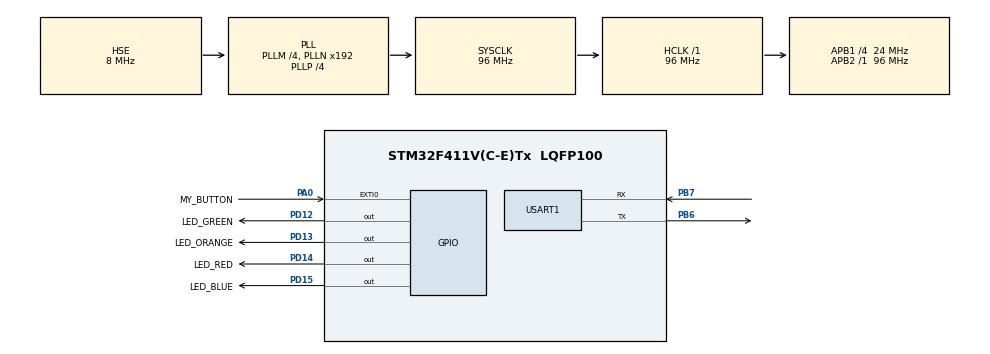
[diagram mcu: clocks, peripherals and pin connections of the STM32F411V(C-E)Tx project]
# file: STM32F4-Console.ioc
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Mcu.Family=STM32F4
Mcu.Name=STM32F411V(C-E)Tx
Mcu.Package=LQFP100
NVIC.EXTI0_IRQn=true\:0\:0\:false\:false\:true\:true\:true\:true
NVIC.PriorityGroup=NVIC_PRIORITYGROUP_0
NVIC.USART1_IRQn=true\:0\:0\:false\:false\:true\:true\:true\:true
PA0-WKUP.GPIO_Label=MY_BUTTON
PA0-WKUP.GPIO_ModeDefaultEXTI=GPIO_MODE_IT_RISING
PA0-WKUP.GPIO_PuPd=GPIO_PULLDOWN
PA0-WKUP.Signal=GPXTI0
PA13.GPIO_Label=SWDIO
PA13.Mode=Serial_Wire
PA13.Signal=SYS_JTMS-SWDIO
PA14.GPIO_Label=SWCLK
PA14.Mode=Serial_Wire
PA14.Signal=SYS_JTCK-SWCLK
PB6.Mode=Asynchronous
PB6.Signal=USART1_TX
PB7.Mode=Asynchronous
PB7.Signal=USART1_RX
PC14-OSC32_IN.GPIO_Label=PC14-OSC32_IN
PC14-OSC32_IN.Mode=LSE-External-Oscillator
PC14-OSC32_IN.Signal=RCC_OSC32_IN
PC15-OSC32_OUT.GPIO_Label=PC15-OSC32_OUT
PC15-OSC32_OUT.Mode=LSE-External-Oscillator
PC15-OSC32_OUT.Signal=RCC_OSC32_OUT
PD12.GPIO_Label=LED_GREEN
PD12.GPIO_PuPd=GPIO_NOPULL
PD12.GPIO_Speed=GPIO_SPEED_FREQ_LOW
PD12.Signal=GPIO_Output
PD13.GPIO_Label=LED_ORANGE
PD13.GPIO_PuPd=GPIO_NOPULL
PD13.GPIO_Speed=GPIO_SPEED_FREQ_LOW
PD13.Signal=GPIO_Output
PD14.GPIO_Label=LED_RED
PD14.GPIO_PuPd=GPIO_NOPULL
PD14.GPIO_Speed=GPIO_SPEED_FREQ_LOW
PD14.Signal=GPIO_Output
PD15.GPIO_Label=LED_BLUE
PD15.GPIO_PuPd=GPIO_NOPULL
PD15.GPIO_Speed=GPIO_SPEED_FREQ_LOW
PD15.Signal=GPIO_Output
PH0\ -\ OSC_IN.GPIO_Label=PH0-OSC_IN
PH0\ -\ OSC_IN.Mode=HSE-External-Oscillator
PH0\ -\ OSC_IN.Signal=RCC_OSC_IN
PH1\ -\ OSC_OUT.GPIO_Label=PH1-OSC_OUT
PH1\ -\ OSC_OUT.Mode=HSE-External-Oscillator
PH1\ -\ OSC_OUT.Signal=RCC_OSC_OUT
ProjectManager.HeapSize=0x200
ProjectManager.StackSize=0x400
ProjectManager.TargetToolchain=STM32CubeIDE
RCC.48MHZClocksFreq_Value=48000000
RCC.AHBFreq_Value=96000000
RCC.APB1CLKDivider=RCC_HCLK_DIV4
RCC.APB1Freq_Value=24000000
RCC.APB1TimFreq_Value=48000000
RCC.APB2Freq_Value=96000000
RCC.APB2TimFreq_Value=96000000
RCC.CortexFreq_Value=96000000
RCC.HCLKFreq_Value=96000000
RCC.HSE_VALUE=8000000
RCC.HSI_VALUE=16000000
RCC.PLLI2SM=5
RCC.PLLI2SN=200
RCC.PLLM=4
RCC.PLLP=RCC_PLLP_DIV4
RCC.PLLQ=8
RCC.PLLSourceVirtual=RCC_PLLSOURCE_HSE
RCC.SYSCLKFreq_VALUE=96000000
RCC.SYSCLKSource=RCC_SYSCLKSOURCE_PLLCLK
RCC.VCOOutputFreq_Value=384000000
USART1.VirtualMode=VM_ASYNC
board=STM32F411E-DISCO

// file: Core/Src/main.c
/* USER CODE BEGIN Header */
/**
  ******************************************************************************
  * @file           : main.c
  * @brief          : Main program body
  ******************************************************************************
  * @attention
  *
  * Copyright (c) 2023 STMicroelectronics.
  * All rights reserved.
  *
  * This software is licensed under terms that can be found in the LICENSE file
  * in the root directory of this software component.
  * If no LICENSE file comes with this software, it is provided AS-IS.
  *
  ******************************************************************************
  */
/* USER CODE END Header */
#include "main.h"

/* USER CODE BEGIN Includes */
#include <stdio.h>
#include <string.h>
#include "console.h"
/* USER CODE END Includes */

UART_HandleTypeDef huart1;

void SystemClock_Config(void);
static void MX_GPIO_Init(void);
static void MX_USART1_UART_Init(void);

/* USER CODE BEGIN 0 */
// ISR - Callback Functions
void HAL_GPIO_EXTI_Callback(uint16_t GPIO_Pin)
{
    if(GPIO_Pin == GPIO_PIN_0){
            HAL_GPIO_TogglePin(LED_BLUE_GPIO_Port, LED_BLUE_Pin);
        }
}

/* USER CODE END 0 */

int main(void)
{

  /* MCU Configuration--------------------------------------------------------*/

  /* Reset of all peripherals, Initializes the Flash interface and the Systick. */
  HAL_Init();

  /* Configure the system clock */
  SystemClock_Config();

  /* Initialize all configured peripherals */
  MX_GPIO_Init();
  MX_USART1_UART_Init();
  /* USER CODE BEGIN 2 */

  printf("Initialization complete.\r\n");
  /* USER CODE END 2 */

  /* Infinite loop */
  /* USER CODE BEGIN WHILE */
  ConsoleInit();
  while (1)
  {

	  //HAL_GPIO_TogglePin(LED_RED_GPIO_Port, LED_RED_Pin);
	  //HAL_Delay(500);
	  ConsoleProcess();

    /* USER CODE END WHILE */

  }
}

void SystemClock_Config(void)
{
  RCC_OscInitTypeDef RCC_OscInitStruct = {0};
  RCC_ClkInitTypeDef RCC_ClkInitStruct = {0};

  /** Configure the main internal regulator output voltage
  */
  __HAL_RCC_PWR_CLK_ENABLE();
  __HAL_PWR_VOLTAGESCALING_CONFIG(PWR_REGULATOR_VOLTAGE_SCALE1);

  /** Initializes the RCC Oscillators according to the specified parameters
  * in the RCC_OscInitTypeDef structure.
  */
  RCC_OscInitStruct.OscillatorType = RCC_OSCILLATORTYPE_HSE;
  RCC_OscInitStruct.HSEState = RCC_HSE_ON;
  RCC_OscInitStruct.PLL.PLLState = RCC_PLL_ON;
  RCC_OscInitStruct.PLL.PLLSource = RCC_PLLSOURCE_HSE;
  RCC_OscInitStruct.PLL.PLLM = 4;
  RCC_OscInitStruct.PLL.PLLN = 192;
  RCC_OscInitStruct.PLL.PLLP = RCC_PLLP_DIV4;
  RCC_OscInitStruct.PLL.PLLQ = 8;
  if (HAL_RCC_OscConfig(&RCC_OscInitStruct) != HAL_OK)
  {
    Error_Handler();
  }

  /** Initializes the CPU, AHB and APB buses clocks
  */
  RCC_ClkInitStruct.ClockType = RCC_CLOCKTYPE_HCLK|RCC_CLOCKTYPE_SYSCLK
                              |RCC_CLOCKTYPE_PCLK1|RCC_CLOCKTYPE_PCLK2;
  RCC_ClkInitStruct.SYSCLKSource = RCC_SYSCLKSOURCE_PLLCLK;
  RCC_ClkInitStruct.AHBCLKDivider = RCC_SYSCLK_DIV1;
  RCC_ClkInitStruct.APB1CLKDivider = RCC_HCLK_DIV4;
  RCC_ClkInitStruct.APB2CLKDivider = RCC_HCLK_DIV1;

  if (HAL_RCC_ClockConfig(&RCC_ClkInitStruct, FLASH_LATENCY_3) != HAL_OK)
  {
    Error_Handler();
  }
}

static void MX_USART1_UART_Init(void)
{

  huart1.Instance = USART1;
  huart1.Init.BaudRate = 115200;
  huart1.Init.WordLength = UART_WORDLENGTH_8B;
  huart1.Init.StopBits = UART_STOPBITS_1;
  huart1.Init.Parity = UART_PARITY_NONE;
  huart1.Init.Mode = UART_MODE_TX_RX;
  huart1.Init.HwFlowCtl = UART_HWCONTROL_NONE;
  huart1.Init.OverSampling = UART_OVERSAMPLING_16;
  if (HAL_UART_Init(&huart1) != HAL_OK)
  {
    Error_Handler();
  }

}

static void MX_GPIO_Init(void)
{
  GPIO_InitTypeDef GPIO_InitStruct = {0};

  /* GPIO Ports Clock Enable */
  __HAL_RCC_GPIOC_CLK_ENABLE();
  __HAL_RCC_GPIOH_CLK_ENABLE();
  __HAL_RCC_GPIOA_CLK_ENABLE();
  __HAL_RCC_GPIOD_CLK_ENABLE();
  __HAL_RCC_GPIOB_CLK_ENABLE();

  /*Configure GPIO pin Output Level */
  HAL_GPIO_WritePin(GPIOD, LED_GREEN_Pin|LED_ORANGE_Pin|LED_RED_Pin|LED_BLUE_Pin, GPIO_PIN_RESET);

  /*Configure GPIO pin : MY_BUTTON_Pin */
  GPIO_InitStruct.Pin = MY_BUTTON_Pin;
  GPIO_InitStruct.Mode = GPIO_MODE_IT_RISING;
  GPIO_InitStruct.Pull = GPIO_PULLDOWN;
  HAL_GPIO_Init(MY_BUTTON_GPIO_Port, &GPIO_InitStruct);

  /*Configure GPIO pins : LED_GREEN_Pin LED_ORANGE_Pin LED_RED_Pin LED_BLUE_Pin */
  GPIO_InitStruct.Pin = LED_GREEN_Pin|LED_ORANGE_Pin|LED_RED_Pin|LED_BLUE_Pin;
  GPIO_InitStruct.Mode = GPIO_MODE_OUTPUT_PP;
  GPIO_InitStruct.Pull = GPIO_NOPULL;
  GPIO_InitStruct.Speed = GPIO_SPEED_FREQ_LOW;
  HAL_GPIO_Init(GPIOD, &GPIO_InitStruct);

  /* EXTI interrupt init*/
  HAL_NVIC_SetPriority(EXTI0_IRQn, 0, 0);
  HAL_NVIC_EnableIRQ(EXTI0_IRQn);

}

/* USER CODE BEGIN 4 */
//Adapted from class comments and Tim's comment here: https://shawnhymel.com/1873/how-to-use-printf-on-stm32/
int __io_putchar(int ch){
	if (HAL_UART_Transmit(&huart1, (uint8_t*)&ch, 1, HAL_MAX_DELAY) != HAL_OK)
		return -1;
	return ch;
}

/* USER CODE END 4 */

void Error_Handler(void)
{
  __disable_irq();
  while (1)
  {
  }
}
